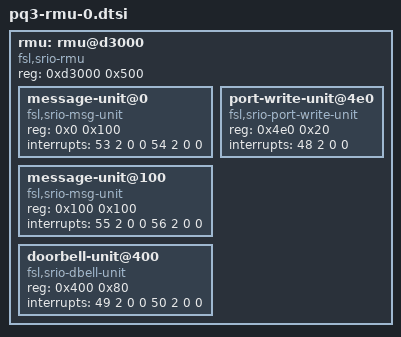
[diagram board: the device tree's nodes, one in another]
/*
 * PQ3 RIO Message Unit device tree stub [ controller @ offset 0xd3000 ]
 *
 * Copyright 2011 Freescale Semiconductor Inc.
 *
 * Redistribution and use in source and binary forms, with or without
 * modification, are permitted provided that the following conditions are met:
 *     * Redistributions of source code must retain the above copyright
 *       notice, this list of conditions and the following disclaimer.
 *     * Redistributions in binary form must reproduce the above copyright
 *       notice, this list of conditions and the following disclaimer in the
 *       documentation and/or other materials provided with the distribution.
 *     * Neither the name of Freescale Semiconductor nor the
 *       names of its contributors may be used to endorse or promote products
 *       derived from this software without specific prior written permission.
 *
 *
 * ALTERNATIVELY, this software may be distributed under the terms of the
 * GNU General Public License ("GPL") as published by the Free Software
 * Foundation, either version 2 of that License or (at your option) any
 * later version.
 *
 * THIS SOFTWARE IS PROVIDED BY Freescale Semiconductor ``AS IS'' AND ANY
 * EXPRESS OR IMPLIED WARRANTIES, INCLUDING, BUT NOT LIMITED TO, THE IMPLIED
 * WARRANTIES OF MERCHANTABILITY AND FITNESS FOR A PARTICULAR PURPOSE ARE
 * DISCLAIMED. IN NO EVENT SHALL Freescale Semiconductor BE LIABLE FOR ANY
 * DIRECT, INDIRECT, INCIDENTAL, SPECIAL, EXEMPLARY, OR CONSEQUENTIAL DAMAGES
 * (INCLUDING, BUT NOT LIMITED TO, PROCUREMENT OF SUBSTITUTE GOODS OR SERVICES;
 * LOSS OF USE, DATA, OR PROFITS; OR BUSINESS INTERRUPTION) HOWEVER CAUSED AND
 * ON ANY THEORY OF LIABILITY, WHETHER IN CONTRACT, STRICT LIABILITY, OR TORT
 * (INCLUDING NEGLIGENCE OR OTHERWISE) ARISING IN ANY WAY OUT OF THE USE OF THIS
 * SOFTWARE, EVEN IF ADVISED OF THE POSSIBILITY OF SUCH DAMAGE.
 */

rmu: rmu@d3000 {
	#address-cells = <1>;
	#size-cells = <1>;
	compatible = "fsl,srio-rmu";
	reg = <0xd3000 0x500>;
	ranges = <0x0 0xd3000 0x500>;

	message-unit@0 {
		compatible = "fsl,srio-msg-unit";
		reg = <0x0 0x100>;
		interrupts = <
			53 2 0 0 /* msg1_tx_irq */
			54 2 0 0>;/* msg1_rx_irq */
	};
	message-unit@100 {
		compatible = "fsl,srio-msg-unit";
		reg = <0x100 0x100>;
		interrupts = <
			55 2 0 0  /* msg2_tx_irq */
			56 2 0 0>;/* msg2_rx_irq */
	};
	doorbell-unit@400 {
		compatible = "fsl,srio-dbell-unit";
		reg = <0x400 0x80>;
		interrupts = <
			49 2 0 0  /* bell_outb_irq */
			50 2 0 0>;/* bell_inb_irq */
	};
	port-write-unit@4e0 {
		compatible = "fsl,srio-port-write-unit";
		reg = <0x4e0 0x20>;
		interrupts = <48 2 0 0>;
	};
};
